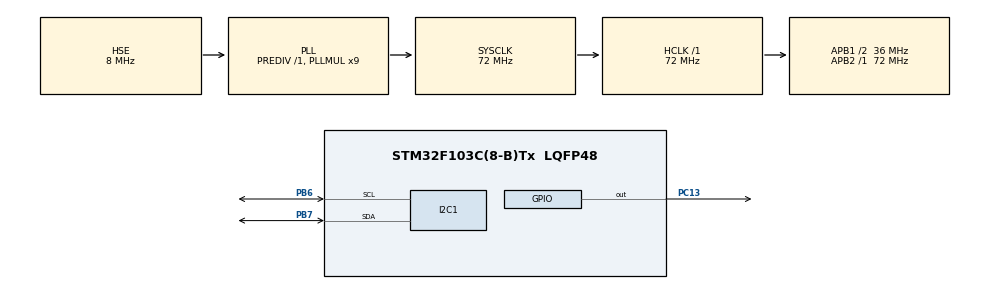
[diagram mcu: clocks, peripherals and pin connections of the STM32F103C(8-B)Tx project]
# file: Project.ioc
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I2C1.I2C_Mode=I2C_Fast
Mcu.Family=STM32F1
Mcu.Name=STM32F103C(8-B)Tx
Mcu.Package=LQFP48
NVIC.PriorityGroup=NVIC_PRIORITYGROUP_4
PA13.Mode=Serial_Wire
PA13.Signal=SYS_JTMS-SWDIO
PA14.Mode=Serial_Wire
PA14.Signal=SYS_JTCK-SWCLK
PB6.Mode=I2C
PB6.Signal=I2C1_SCL
PB7.Mode=I2C
PB7.Signal=I2C1_SDA
PC13-TAMPER-RTC.Signal=GPIO_Output
PD0-OSC_IN.Mode=HSE-External-Oscillator
PD0-OSC_IN.Signal=RCC_OSC_IN
PD1-OSC_OUT.Mode=HSE-External-Oscillator
PD1-OSC_OUT.Signal=RCC_OSC_OUT
ProjectManager.HeapSize=0x200
ProjectManager.StackSize=0x400
ProjectManager.TargetToolchain=MDK-ARM V5.32
RCC.AHBFreq_Value=72000000
RCC.APB1CLKDivider=RCC_HCLK_DIV2
RCC.APB1Freq_Value=36000000
RCC.APB1TimFreq_Value=72000000
RCC.APB2Freq_Value=72000000
RCC.APB2TimFreq_Value=72000000
RCC.HCLKFreq_Value=72000000
RCC.PLLMUL=RCC_PLL_MUL9
RCC.PLLSourceVirtual=RCC_PLLSOURCE_HSE
RCC.SYSCLKFreq_VALUE=72000000
RCC.SYSCLKSource=RCC_SYSCLKSOURCE_PLLCLK
RCC.USBFreq_Value=72000000
board=custom

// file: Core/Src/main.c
/* USER CODE BEGIN Header */
/**
  ******************************************************************************
  * @file           : main.c
  * @brief          : Main program body
  ******************************************************************************
  * @attention
  *
  * Copyright (c) 2025 STMicroelectronics.
  * All rights reserved.
  *
  * This software is licensed under terms that can be found in the LICENSE file
  * in the root directory of this software component.
  * If no LICENSE file comes with this software, it is provided AS-IS.
  *
  ******************************************************************************
  */
/* USER CODE END Header */
#include "main.h"
#include "i2c.h"
#include "gpio.h"

/* USER CODE BEGIN Includes */
#include "OLED.h"
/* USER CODE END Includes */

void SystemClock_Config(void);

int main(void)
{

    /* MCU Configuration--------------------------------------------------------*/

    /* Reset of all peripherals, Initializes the Flash interface and the Systick. */
    HAL_Init();

    /* Configure the system clock */
    SystemClock_Config();

    /* Initialize all configured peripherals */
    MX_GPIO_Init();
    MX_I2C1_Init();
    /* USER CODE BEGIN 2 */
    OLED_Init();

    OLED_ShowChar(0, 0, 'A', OLED_8X16);
    //OLED_ShowString(16, 0, "Hello World!", OLED_8X16);
    OLED_ShowChar(0, 18, 'A', OLED_6X8);
    //OLED_ShowString(16, 18, "Hello World!", OLED_6X8);
    OLED_ShowNum(0, 28, 12345, 5, OLED_6X8);
    OLED_ShowSignedNum(40, 28, -66, 2, OLED_6X8);
    OLED_ShowHexNum(70, 28, 0xA5A5, 4, OLED_6X8);
    OLED_ShowBinNum(0, 38, 0xA5, 8, OLED_6X8);
    OLED_ShowFloatNum(60, 38, 123.45, 3, 2, OLED_6X8);
    //OLED_ShowString(0, 48, "Hello,世界。", OLED_8X16);
    //OLED_ShowString(0, 48, "Hello?", OLED_8X16);
    OLED_ShowImage(96, 48, 16, 16, Diode);
    OLED_Printf(96, 18, OLED_6X8, "[%02d]", 6);
    OLED_Update();

    HAL_Delay(3000);
    OLED_Clear();
    /*在(5, 8)位置画点*/
    OLED_DrawPoint(5, 8);
    /*获取(5, 8)位置的点*/
    if (OLED_GetPoint(5, 8))
    {
        /*如果指定点点亮，则在(10, 4)位置显示字符串"YES"，字体大小为6*8点阵*/
        OLED_ShowString(10, 4, "YES", OLED_6X8);
    }
    else
    {
        /*如果指定点未点亮，则在(10, 4)位置显示字符串"NO "，字体大小为6*8点阵*/
        OLED_ShowString(10, 4, "NO ", OLED_6X8);
    }
    /*在(40, 0)和(127, 15)位置之间画直线*/
    OLED_DrawLine(40, 0, 127, 15);
    /*在(40, 15)和(127, 0)位置之间画直线*/
    OLED_DrawLine(40, 15, 127, 0);
    /*在(0, 20)位置画矩形，宽12像素，高15像素，未填充*/
    OLED_DrawRectangle(0, 20, 12, 15, OLED_UNFILLED);
    /*在(0, 40)位置画矩形，宽12像素，高15像素，填充*/
    OLED_DrawRectangle(0, 40, 12, 15, OLED_FILLED);
    /*在(20, 20)、(40, 25)和(30, 35)位置之间画三角形，未填充*/
    OLED_DrawTriangle(20, 20, 40, 25, 30, 35, OLED_UNFILLED);
    /*在(20, 40)、(40, 45)和(30, 55)位置之间画三角形，填充*/
    OLED_DrawTriangle(20, 40, 40, 45, 30, 55, OLED_FILLED);
    /*在(55, 27)位置画圆，半径8像素，未填充*/
    OLED_DrawCircle(55, 27, 8, OLED_UNFILLED);
    /*在(55, 47)位置画圆，半径8像素，填充*/
    OLED_DrawCircle(55, 47, 8, OLED_FILLED);
    /*在(82, 27)位置画椭圆，横向半轴12像素，纵向半轴8像素，未填充*/
    OLED_DrawEllipse(82, 27, 12, 8, OLED_UNFILLED);
    /*在(82, 47)位置画椭圆，横向半轴12像素，纵向半轴8像素，填充*/
    OLED_DrawEllipse(82, 47, 12, 8, OLED_FILLED);
    /*在(110, 18)位置画圆弧，半径15像素，起始角度25度，终止角度125度，未填充*/
    OLED_DrawArc(110, 18, 15, 25, 125, OLED_UNFILLED);
    /*在(110, 38)位置画圆弧，半径15像素，起始角度25度，终止角度125度，填充*/
    OLED_DrawArc(110, 38, 15, 25, 125, OLED_FILLED);
    OLED_Update();
    HAL_Delay(3000);

    /* USER CODE END 2 */

    /* Infinite loop */
    /* USER CODE BEGIN WHILE */
    while (1)
    {
        for (uint8_t i = 0; i < 4; i ++)
        {
            /*将OLED显存数组部分数据取反，从(0, i * 16)位置开始，宽128像素，高16像素*/
            OLED_ReverseArea(0, i * 16, 128, 16);
            OLED_Update();
            HAL_Delay(1000);
            /*把取反的内容翻转回来*/
            OLED_ReverseArea(0, i * 16, 128, 16);
        }
        /*将OLED显存数组全部数据取反*/
        OLED_Reverse();
        OLED_Update();
        HAL_Delay(1000);
        /* USER CODE END WHILE */

    }
}

void SystemClock_Config(void)
{
    RCC_OscInitTypeDef RCC_OscInitStruct = {0};
    RCC_ClkInitTypeDef RCC_ClkInitStruct = {0};

    /** Initializes the RCC Oscillators according to the specified parameters
    * in the RCC_OscInitTypeDef structure.
    */
    RCC_OscInitStruct.OscillatorType = RCC_OSCILLATORTYPE_HSE;
    RCC_OscInitStruct.HSEState = RCC_HSE_ON;
    RCC_OscInitStruct.HSEPredivValue = RCC_HSE_PREDIV_DIV1;
    RCC_OscInitStruct.HSIState = RCC_HSI_ON;
    RCC_OscInitStruct.PLL.PLLState = RCC_PLL_ON;
    RCC_OscInitStruct.PLL.PLLSource = RCC_PLLSOURCE_HSE;
    RCC_OscInitStruct.PLL.PLLMUL = RCC_PLL_MUL9;
    if (HAL_RCC_OscConfig(&RCC_OscInitStruct) != HAL_OK)
    {
        Error_Handler();
    }

    /** Initializes the CPU, AHB and APB buses clocks
    */
    RCC_ClkInitStruct.ClockType = RCC_CLOCKTYPE_HCLK|RCC_CLOCKTYPE_SYSCLK
                                  |RCC_CLOCKTYPE_PCLK1|RCC_CLOCKTYPE_PCLK2;
    RCC_ClkInitStruct.SYSCLKSource = RCC_SYSCLKSOURCE_PLLCLK;
    RCC_ClkInitStruct.AHBCLKDivider = RCC_SYSCLK_DIV1;
    RCC_ClkInitStruct.APB1CLKDivider = RCC_HCLK_DIV2;
    RCC_ClkInitStruct.APB2CLKDivider = RCC_HCLK_DIV1;

    if (HAL_RCC_ClockConfig(&RCC_ClkInitStruct, FLASH_LATENCY_2) != HAL_OK)
    {
        Error_Handler();
    }
}

void Error_Handler(void)
{
    __disable_irq();
    while (1)
    {
    }
}
